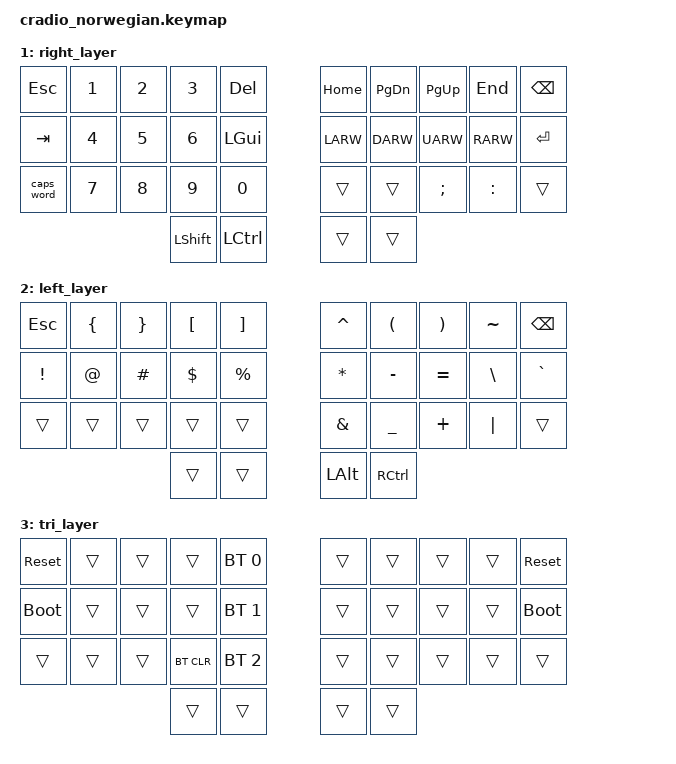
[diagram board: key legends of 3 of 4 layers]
// Copyright (c) 2022 The ZMK Contributors
// SPDX-License-Identifier: MIT

#include <behaviors.dtsi>
#include <dt-bindings/zmk/keys.h>
#include <dt-bindings/zmk/bt.h>

// Home row mods macro, need to change
#define HRML(k1,k2,k3,k4) &ht LSHFT k1  &ht LALT k2  &ht LCTRL k3  &ht LGUI k4
#define HRMR(k1,k2,k3,k4) &ht RGUI k1  &ht RCTRL k2  &ht RALT k3  &ht RSHFT k4

/ {
    behaviors {
        ht: hold_tap {
            label = "hold_tap";
            compatible = "zmk,behavior-hold-tap";
            #binding-cells = <2>;
            flavor = "tap-preferred";
            tapping-term-ms = <220>;
            quick-tap-ms = <150>;
            global-quick-tap;
            bindings = <&kp>, <&kp>;
        };
        td: tapdance {
            compatible = "zmk,behavior-hold-tap";
            label = "TAPDANCE";
            #binding-cells = <2>;
            tapping-term-ms = <150>;
            quick_tap_ms = <0>;
            flavor = "tap-preferred";
            bindings = <&kp>, <&kp>;
        };
    };

    conditional_layers {
        compatible = "zmk,conditional-layers";
        tri_layer {
            if-layers = <1 2>;
            then-layer = <3>;
        };
    };

    keymap {
        compatible = "zmk,keymap";
        default_layer {
            bindings = <
        //╭──────────┬──────────┬──────────┬──────────┬──────────╮   ╭──────────┬──────────┬──────────┬──────────┬──────────╮
        //│  Q       │  W       │  E       │  R       │  T       │   │  Y       │  U       │  I       │  O       │  P       │
            &kp Q      &kp W      &kp E      &kp R      &kp T          &kp Y      &kp U      &kp I      &kp O      &kp P
        //├──────────┼──────────┼──────────┼──────────┼──────────┤   ├──────────┼──────────┼──────────┼──────────┼──────────┤
        //│  A       │  S       │  D       │  F       │  G       │   │  H       │  J       │  K       │  L       │ æ Æ      │
            HRML(A,        S,         D,         F)     &kp G          &kp H      HRMR(J,        K,         L,        SQT)
        //├──────────┼──────────┼──────────┼──────────┼──────────┤   ├──────────┼──────────┼──────────┼──────────┼──────────┤
        //│  Z       │  X       │  C       │  V       │  B       │   │  N       │  M       │ , ;      │ . :      │ - _      │
            &kp Z      &kp X      &kp C      &kp V      &kp B          &kp N      &kp M      &kp COMMA  &kp DOT    &kp FSLH
        //╰──────────┴──────────┴──────────┼──────────┼──────────┤   ├──────────┼──────────┼──────────┴──────────┴──────────╯
                                         &lt 2 TAB  &td LCTRL ENTER &td RSHFT SPACE  &lt 1 BSPC
        //                                 ╰──────────┴──────────╯   ╰──────────┴──────────╯
            >;
        };

        right_layer {
            bindings = <
        //╭──────────┬──────────┬──────────┬──────────┬──────────╮   ╭──────────┬──────────┬──────────┬──────────┬──────────╮
        //│ ESC      │  1       │  2       │  3       │ DELETE   │   │ HOME     │ PAGE DN  │ PAGE UP  │ END      │  BSPC    │
            &kp ESC    &kp N1     &kp N2     &kp N3     &kp DEL        &kp HOME   &kp PG_DN  &kp PG_UP  &kp END    &kp BSPC 
        //├──────────┼──────────┼──────────┼──────────┼──────────┤   ├──────────┼──────────┼──────────┼──────────┼──────────┤
        //│ TAB      │  4       │  5       │  6       │ WINDOWS  │   │ LEFT     │ DOWN     │ UP       │ RIGHT    │  ENTER   │
            &kp TAB    &kp N4     &kp N5     &kp N6     &kp LGUI       &kp LARW   &kp DARW   &kp UARW   &kp RARW   &kp ENTER
        //├──────────┼──────────┼──────────┼──────────┼──────────┤   ├──────────┼──────────┼──────────┼──────────┼──────────┤
        //│ CAPS     │  7       │  8       │  9       │  0       │   │          │          │  ø       │  Ø       │          │
           &caps_word  &kp N7     &kp N8     &kp N9     &kp N0         &trans     &trans     &kp SEMI   &kp COLON  &trans
        //╰──────────┴──────────┴──────────┼──────────┼──────────┤   ├──────────┼──────────┼──────────┴──────────┴──────────╯
                                             &kp LSHFT  &kp LCTRL      &trans     &trans
        //                                 ╰──────────┴──────────╯   ╰──────────┴──────────╯
            >;
        };

        left_layer {
            bindings = <
        //╭──────────┬──────────┬──────────┬──────────┬──────────╮   ╭──────────┬──────────┬──────────┬──────────┬──────────╮
        //│ ESC      │  Å       │  ^       │  å       │  ¨       │   │  &       │  )       │  =       │  §       │  BSPC    │
            &kp ESC    &kp LBRC   &kp RBRC   &kp LBKT   &kp RBKT       &kp CARET  &kp LPAR   &kp RPAR   &kp TILDE  &kp BSPC 
        //├──────────┼──────────┼──────────┼──────────┼──────────┤   ├──────────┼──────────┼──────────┼──────────┼──────────┤
        //│  !       │  "       │  #       │  ¤       │  %       │   │  (       │  +       │  \       │  '       │  |       │
            &kp EXCL   &kp AT     &kp HASH   &kp DLLR   &kp PRCNT      &kp ASTRK  &kp MINUS  &kp EQUAL  &kp BSLH   &kp GRAVE
        //├──────────┼──────────┼──────────┼──────────┼──────────┤   ├──────────┼──────────┼──────────┼──────────┼──────────┤
        //│          │          │          │          │          │   │  /       │  ?       │  `       │  *       │          │
            &trans     &trans     &trans     &trans     &trans         &kp AMPS   &kp UNDER  &kp PLUS   &kp PIPE   &trans
        //╰──────────┴──────────┴──────────┼──────────┼──────────┤   ├──────────┼──────────┼──────────┴──────────┴──────────╯
                                             &trans     &trans         &kp LALT   &kp RCTRL
        //                                 ╰──────────┴──────────╯   ╰──────────┴──────────╯
            >;
        };

        tri_layer {
            bindings = <
        //╭──────────┬──────────┬──────────┬──────────┬──────────╮   ╭──────────┬──────────┬──────────┬──────────┬──────────╮
        //│ RESET    │          │          │          │PROFILE 0 │   │          │          │          │          │  RESET   │
           &sys_reset  &trans     &trans     &trans    &bt BT_SEL 0    &trans     &trans     &trans     &trans    &sys_reset
        //├──────────┼──────────┼──────────┼──────────┼──────────┤   ├──────────┼──────────┼──────────┼──────────┼──────────┤
        //│BOOTLOADER│          │          │          │PROFILE 1 │   │          │          │          │          │BOOTLOADER│
          &bootloader  &trans     &trans     &trans    &bt BT_SEL 1    &trans     &trans     &trans     &trans    &bootloader
        //├──────────┼──────────┼──────────┼──────────┼──────────┤   ├──────────┼──────────┼──────────┼──────────┼──────────┤
        //│          │          │          │ CLEAR BT │PROFILE 2 │   │          │          │          │          │          │
            &trans     &trans     &trans    &bt BT_CLR &bt BT_SEL 2    &trans     &trans     &trans     &trans     &trans
        //╰──────────┴──────────┴──────────┼──────────┼──────────┤   ├──────────┼──────────┼──────────┴──────────┴──────────╯
                                             &trans     &trans         &trans     &trans
        //                                 ╰──────────┴──────────╯   ╰──────────┴──────────╯
            >;
        };
    };
};
